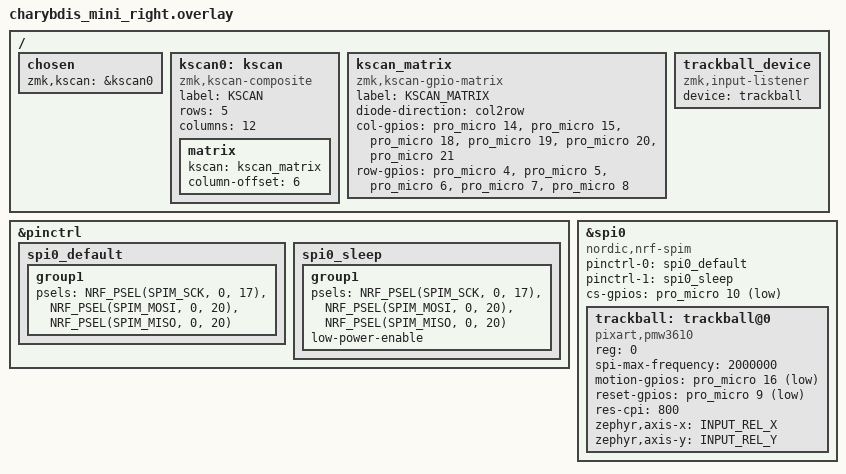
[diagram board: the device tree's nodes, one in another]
#include <dt-bindings/input/input-event-codes.h>
#include "charybdis_mini.dtsi"

/ {
    chosen {
        zmk,kscan = &kscan0;
    };

    kscan0: kscan {
        compatible = "zmk,kscan-composite";
        label = "KSCAN";
        rows = <5>;
        columns = <12>;

        matrix: matrix {
            kscan = <&kscan_matrix>;
            column-offset = <6>;
        };
    };

    kscan_matrix: kscan_matrix {
        compatible = "zmk,kscan-gpio-matrix";
        label = "KSCAN_MATRIX";
    diode-direction = "col2row";

    col-gpios
        = <&pro_micro 14 GPIO_ACTIVE_HIGH>
        , <&pro_micro 15 GPIO_ACTIVE_HIGH>
        , <&pro_micro 18 GPIO_ACTIVE_HIGH>
        , <&pro_micro 19 GPIO_ACTIVE_HIGH>
        , <&pro_micro 20 GPIO_ACTIVE_HIGH>
        , <&pro_micro 21 GPIO_ACTIVE_HIGH>
        ;

        row-gpios
            = <&pro_micro 4 (GPIO_ACTIVE_HIGH | GPIO_PULL_DOWN)>
            , <&pro_micro 5 (GPIO_ACTIVE_HIGH | GPIO_PULL_DOWN)>
            , <&pro_micro 6 (GPIO_ACTIVE_HIGH | GPIO_PULL_DOWN)>
            , <&pro_micro 7 (GPIO_ACTIVE_HIGH | GPIO_PULL_DOWN)>
            , <&pro_micro 8 (GPIO_ACTIVE_HIGH | GPIO_PULL_DOWN)>
            ;
    };
};

&pinctrl {
    spi0_default: spi0_default {
        group1 {
            psels = <NRF_PSEL(SPIM_SCK, 0, 17)>,
                <NRF_PSEL(SPIM_MOSI, 0, 20)>,
                <NRF_PSEL(SPIM_MISO, 0, 20)>; /* MOSI and MISO are same for PMW3610 */
        };
    };

    spi0_sleep: spi0_sleep {
        group1 {
            psels = <NRF_PSEL(SPIM_SCK, 0, 17)>,
                <NRF_PSEL(SPIM_MOSI, 0, 20)>,
                <NRF_PSEL(SPIM_MISO, 0, 20)>;
            low-power-enable;
        };
    };
};

&spi0 {
    status = "okay";
    compatible = "nordic,nrf-spim";
    pinctrl-0 = <&spi0_default>;
    pinctrl-1 = <&spi0_sleep>;
    pinctrl-names = "default", "sleep";
    cs-gpios = <&pro_micro 10 GPIO_ACTIVE_LOW>;

    trackball: trackball@0 {
        status = "okay";
        compatible = "pixart,pmw3610";
        reg = <0>;
        spi-max-frequency = <2000000>;
        motion-gpios = <&pro_micro 16 (GPIO_ACTIVE_LOW | GPIO_PULL_UP)>;
        reset-gpios = <&pro_micro 9 GPIO_ACTIVE_LOW>;
        res-cpi = <800>;
        zephyr,axis-x = <INPUT_REL_X>;
        zephyr,axis-y = <INPUT_REL_Y>;
        /* sensitivity = <2>; */
    };
};

/ {
  trackball_device {
    compatible = "zmk,input-listener";
    device = <&trackball>;
  };
};
